AUTOSAR XML (schema 4-0-3)
standard types defined: Boolean, UInt8
package /AUTOSAR_Platform/DataConstrs
  range DC_Boolean: raw 0..1
package /DataTypes/Units
  unit NoUnit1: display-name=NoUnit, factor-si-to-unit=1, offset-si-to-unit=0
package /PATAC/Facility/DataTypes/Implementation
  compu method COMPU_Boolean: 0=FALSE, 1=TRUE
  unit NoUnit: factor-si-to-unit=1, offset-si-to-unit=0
package /PATAC/MSM/DataTypes/ImplementationDataTypes
  impl type IfVeSMSeStNumConfig: category=VALUE, base-type=UInt8, sw-calibration-access=READ-ONLY, compu {0=SeatNum4Config, 1=SeatNum6Config, 2=SeatNum7Config, 3=SeatNum4PConfig, 4=SeatNumNDLBLow, 5=SeatNumNDLBHigh}, type-emitter=RTE
  impl type IntCnt: category=VALUE, base-type=UInt8, sw-calibration-access=READ-ONLY, type-emitter=RTE
  impl type IntEnable: category=VALUE, base-type=Boolean, sw-calibration-access=READ-ONLY, type-emitter=RTE
package /PATAC/MSM/ModeAdjust
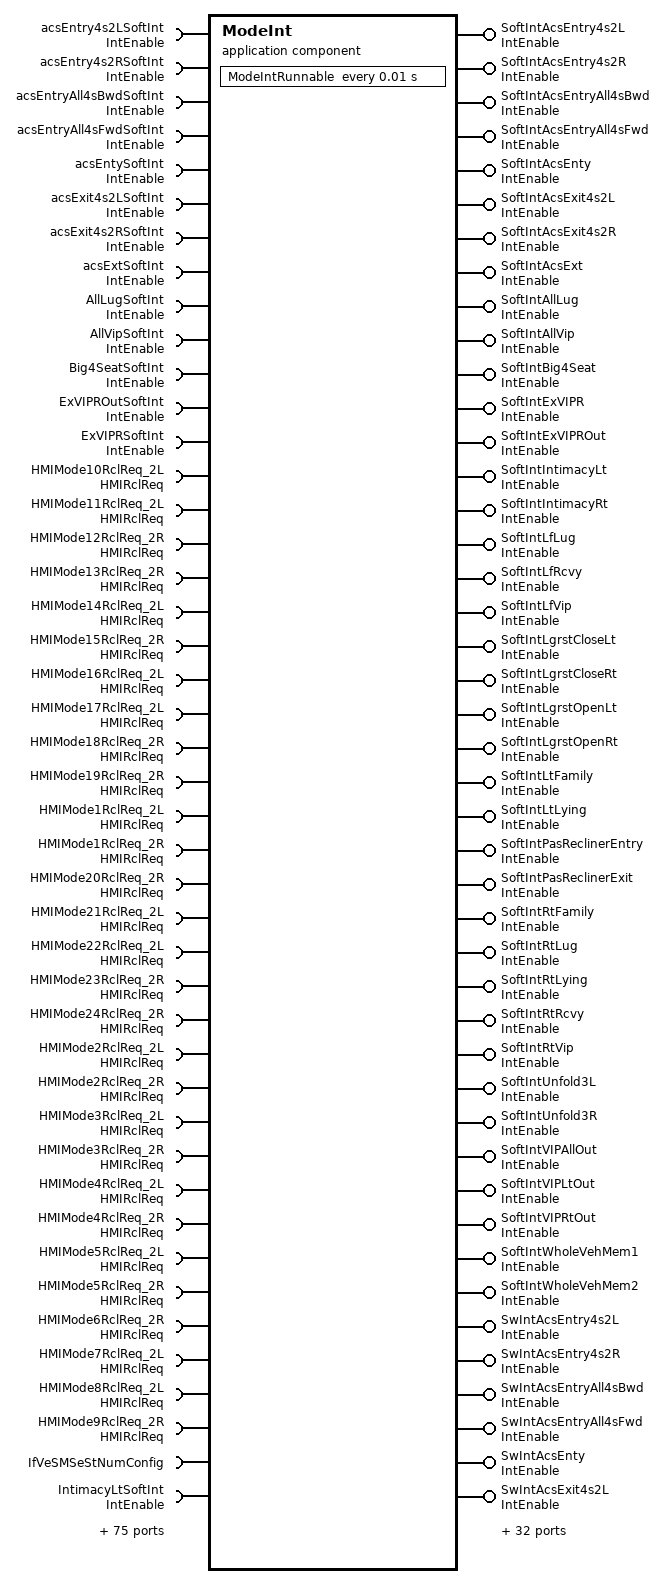
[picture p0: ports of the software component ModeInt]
  application sw component type ModeInt
    76 x provide port, all with provided-interface=IntEnable:
      SoftIntAcsEntry4s2L: nonqueued-sender-com-spec{data-element=IntEnable/Val, init-value=ComSpec59f96da2_7120eeaaf3e8fd53:0}
      SoftIntAcsEntry4s2R: nonqueued-sender-com-spec{data-element=IntEnable/Val, init-value=ComSpec188b96a0_423124f0f088183b:0}
      SoftIntAcsEntryAll4sBwd: nonqueued-sender-com-spec{data-element=IntEnable/Val, init-value=ComSpec659958fd_9c26f3706bd66cb5:0}
      SoftIntAcsEntryAll4sFwd: nonqueued-sender-com-spec{data-element=IntEnable/Val, init-value=ComSpec65858428_b3ed7bfb3665fd2b:0}
      SoftIntAcsEnty: nonqueued-sender-com-spec{data-element=IntEnable/Val, init-value=ComSpecc3d9fe5d_26040a192377f9e4:0}
      SoftIntAcsExit4s2L: nonqueued-sender-com-spec{data-element=IntEnable/Val, init-value=ComSpec2f50422d_f66996e724c9b7d0:0}
      SoftIntAcsExit4s2R: nonqueued-sender-com-spec{data-element=IntEnable/Val, init-value=ComSpeccde21871_e71db2d184100505:0}
      SoftIntAcsExt: nonqueued-sender-com-spec{data-element=IntEnable/Val, init-value=ComSpec899aba2d_12feed9e9f306d84:0}
      SoftIntAllLug: nonqueued-sender-com-spec{data-element=IntEnable/Val, init-value=ComSpecb3b8c25f_afafc56442f97f2f:0}
      SoftIntAllVip: nonqueued-sender-com-spec{data-element=IntEnable/Val, init-value=ComSpeca1d71ad4_c5481bbab1153ece:0}
      SoftIntBig4Seat: nonqueued-sender-com-spec{data-element=IntEnable/Val, init-value=0}
      SoftIntExVIPR: nonqueued-sender-com-spec{data-element=IntEnable/Val, init-value=0}
      SoftIntExVIPROut: nonqueued-sender-com-spec{data-element=IntEnable/Val, init-value=0}
      SoftIntIntimacyLt: nonqueued-sender-com-spec{data-element=IntEnable/Val, init-value=ComSpec179d4aec_8b8d804c9de5a832:0}
      SoftIntIntimacyRt: nonqueued-sender-com-spec{data-element=IntEnable/Val, init-value=ComSpece128a0c0_0fd8747b7173239b:0}
      SoftIntLfLug: nonqueued-sender-com-spec{data-element=IntEnable/Val, init-value=ComSpece807cf11_91c2ff9d50d5acbd:0}
      SoftIntLfRcvy: nonqueued-sender-com-spec{data-element=IntEnable/Val, init-value=ComSpecf2ff96a5_192105ae2675aaf7:0}
      SoftIntLfVip: nonqueued-sender-com-spec{data-element=IntEnable/Val, init-value=ComSpec8127e56c_ef9d14cff893367e:0}
      SoftIntLgrstCloseLt: nonqueued-sender-com-spec{data-element=IntEnable/Val, init-value=ComSpecd43ef14f_51d6d7e3885dd74d:0}
      SoftIntLgrstCloseRt: nonqueued-sender-com-spec{data-element=IntEnable/Val, init-value=ComSpecd6d83571_8de76a0bc78fde80:0}
      SoftIntLgrstOpenLt: nonqueued-sender-com-spec{data-element=IntEnable/Val, init-value=ComSpec41af1a4f_f741a1cbd52ea939:0}
      SoftIntLgrstOpenRt: nonqueued-sender-com-spec{data-element=IntEnable/Val, init-value=ComSpecbefe6405_6f1c2904a5660aca:0}
      SoftIntLtFamily: nonqueued-sender-com-spec{data-element=IntEnable/Val, init-value=ComSpecf3068dab_be17da265e3b369f:0}
      SoftIntLtLying: nonqueued-sender-com-spec{data-element=IntEnable/Val, init-value=ComSpec41634c5a_24a1ae597b892c7e:0}
      SoftIntPasReclinerEntry: nonqueued-sender-com-spec{data-element=IntEnable/Val, init-value=ComSpec5174c602_8624e7747eaef3d9:0}
      SoftIntPasReclinerExit: nonqueued-sender-com-spec{data-element=IntEnable/Val, init-value=ComSpec88456c9d_079221d12eb33f36:0}
      SoftIntRtFamily: nonqueued-sender-com-spec{data-element=IntEnable/Val, init-value=ComSpec6bdeb8e2_9f608aa14f83c2ef:0}
      SoftIntRtLug: nonqueued-sender-com-spec{data-element=IntEnable/Val, init-value=ComSpec31871b14_19a3da55a16d08b9:0}
      SoftIntRtLying: nonqueued-sender-com-spec{data-element=IntEnable/Val, init-value=ComSpecb43ed3d5_9c183203f17d7c39:0}
      SoftIntRtRcvy: nonqueued-sender-com-spec{data-element=IntEnable/Val, init-value=ComSpec0c8ac4fd_05f7ee5b718f0b60:0}
      SoftIntRtVip: nonqueued-sender-com-spec{data-element=IntEnable/Val, init-value=ComSpec0e3a052e_e0a08b00a2b52453:0}
      SoftIntUnfold3L: nonqueued-sender-com-spec{data-element=IntEnable/Val, init-value=0}
      SoftIntUnfold3R: nonqueued-sender-com-spec{data-element=IntEnable/Val, init-value=0}
      SoftIntVIPAllOut: nonqueued-sender-com-spec{data-element=IntEnable/Val, init-value=ComSpec9d458944_6a58e494fda9435a:0}
      SoftIntVIPLtOut: nonqueued-sender-com-spec{data-element=IntEnable/Val, init-value=ComSpec3fe9d267_b5ef9a6cf583b00d:0}
      SoftIntVIPRtOut: nonqueued-sender-com-spec{data-element=IntEnable/Val, init-value=ComSpec14da6a61_1cd6682ed1dd175b:0}
      SoftIntWholeVehMem1: nonqueued-sender-com-spec{data-element=IntEnable/Val, init-value=0}
      SoftIntWholeVehMem2: nonqueued-sender-com-spec{data-element=IntEnable/Val, init-value=0}
      SwIntAcsEntry4s2L: nonqueued-sender-com-spec{data-element=IntEnable/Val, init-value=ComSpec5b381a05_20a420dcaf653946:0}
      SwIntAcsEntry4s2R: nonqueued-sender-com-spec{data-element=IntEnable/Val, init-value=ComSpec08dbcf5e_623373ab2a54adc4:0}
      SwIntAcsEntryAll4sBwd: nonqueued-sender-com-spec{data-element=IntEnable/Val, init-value=ComSpec2acac57c_83e28e6252a86cec:0}
      SwIntAcsEntryAll4sFwd: nonqueued-sender-com-spec{data-element=IntEnable/Val, init-value=ComSpecb3bc0b71_9a1b690978a523bd:0}
      SwIntAcsEnty: nonqueued-sender-com-spec{data-element=IntEnable/Val, init-value=ComSpec815b8781_0bbd995141a2ae08:0}
      SwIntAcsExit4s2L: nonqueued-sender-com-spec{data-element=IntEnable/Val, init-value=ComSpecb208aba7_4f2c212f3d748e34:0}
      SwIntAcsExit4s2R: nonqueued-sender-com-spec{data-element=IntEnable/Val, init-value=ComSpecab9794b0_e6ed6e27ff51b9fa:0}
      SwIntAcsExt: nonqueued-sender-com-spec{data-element=IntEnable/Val, init-value=ComSpecd839f9e4_f74d7836726247ea:0}
      SwIntAllLug: nonqueued-sender-com-spec{data-element=IntEnable/Val, init-value=ComSpec1f44a83d_0c3f442d2dd8c614:0}
      SwIntAllVip: nonqueued-sender-com-spec{data-element=IntEnable/Val, init-value=ComSpeccc0c7db5_08b538b43a0752a9:0}
      SwIntAllVipOut: nonqueued-sender-com-spec{data-element=IntEnable/Val, init-value=0}
      SwIntBig4Seat: nonqueued-sender-com-spec{data-element=IntEnable/Val, init-value=0}
      SwIntExVIPR: nonqueued-sender-com-spec{data-element=IntEnable/Val, init-value=0}
      SwIntExVIPROut: nonqueued-sender-com-spec{data-element=IntEnable/Val, init-value=0}
      SwIntIntimacyLt: nonqueued-sender-com-spec{data-element=IntEnable/Val, init-value=ComSpeced1880dd_7f049cd17b79689a:0}
      SwIntIntimacyRt: nonqueued-sender-com-spec{data-element=IntEnable/Val, init-value=ComSpec82f33741_a070fa978900dd49:0}
      SwIntLfLug: nonqueued-sender-com-spec{data-element=IntEnable/Val, init-value=ComSpec1d835650_9f2d33f93bae7e2d:0}
      SwIntLfRcvy: nonqueued-sender-com-spec{data-element=IntEnable/Val, init-value=ComSpeca2d8a846_f1765e4b963d308a:0}
      SwIntLfVip: nonqueued-sender-com-spec{data-element=IntEnable/Val, init-value=ComSpec5ae82a95_8b538ef9cf021bb9:0}
      SwIntLfVipOut: nonqueued-sender-com-spec{data-element=IntEnable/Val, init-value=0}
      SwIntLgrstCloseLt: nonqueued-sender-com-spec{data-element=IntEnable/Val, init-value=ComSpec37957095_1f6be46bc34810ce:0}
      SwIntLgrstCloseRt: nonqueued-sender-com-spec{data-element=IntEnable/Val, init-value=ComSpec7bfebc29_3b30ba1fa7bdbeff:0}
      SwIntLgrstOpenLt: nonqueued-sender-com-spec{data-element=IntEnable/Val, init-value=ComSpecda775f0f_101109881c7da9c7:0}
      SwIntLgrstOpenRt: nonqueued-sender-com-spec{data-element=IntEnable/Val, init-value=ComSpec630e8cc5_d01f660af315f5d8:0}
      SwIntLtFamily: nonqueued-sender-com-spec{data-element=IntEnable/Val, init-value=ComSpeca8acf676_6206e2a0c6bca466:0}
      SwIntLtLying: nonqueued-sender-com-spec{data-element=IntEnable/Val, init-value=ComSpec22b14825_94d9dfc41c8f591b:0}
      SwIntPasReclinerEntry: nonqueued-sender-com-spec{data-element=IntEnable/Val, init-value=ComSpec2817485a_c93ad14cb402e925:0}
      SwIntPasReclinerExit: nonqueued-sender-com-spec{data-element=IntEnable/Val, init-value=ComSpecee27f8bf_7800ff2246ae725c:0}
      SwIntRtFamily: nonqueued-sender-com-spec{data-element=IntEnable/Val, init-value=ComSpecff73a571_d104911f83169a22:0}
      SwIntRtLug: nonqueued-sender-com-spec{data-element=IntEnable/Val, init-value=ComSpec73fd1a62_e7a0e89016c609a2:0}
      SwIntRtLying: nonqueued-sender-com-spec{data-element=IntEnable/Val, init-value=ComSpec24405ce7_da40e6512a24f22a:0}
      SwIntRtRcvy: nonqueued-sender-com-spec{data-element=IntEnable/Val, init-value=ComSpec96664597_38534832cbc35c95:0}
      SwIntRtVip: nonqueued-sender-com-spec{data-element=IntEnable/Val, init-value=ComSpec347f2341_073160147a5bf2ad:0}
      SwIntRtVipOut: nonqueued-sender-com-spec{data-element=IntEnable/Val, init-value=0}
      SwIntUnfold3L: nonqueued-sender-com-spec{data-element=IntEnable/Val, init-value=ComSpec5899eaf1_eb0de24a74093078:0}
      SwIntUnfold3R: nonqueued-sender-com-spec{data-element=IntEnable/Val, init-value=ComSpecc1b8f339_34e92b2b21141ee2:0}
      SwIntWholeVehMem1: nonqueued-sender-com-spec{data-element=IntEnable/Val, init-value=0}
      SwIntWholeVehMem2: nonqueued-sender-com-spec{data-element=IntEnable/Val, init-value=0}
    119 x require port:
      acsEntry4s2LSoftInt: nonqueued-receiver-com-spec{data-element=IntEnable/Val, filter=data-filter-type=ALWAYS, init-value=ComSpec59bedbba_d8fc4b3de43f23dd:0}, required-interface=IntEnable
      acsEntry4s2RSoftInt: nonqueued-receiver-com-spec{data-element=IntEnable/Val, filter=data-filter-type=ALWAYS, init-value=ComSpec9d818e9f_9fc340a7e822681f:0}, required-interface=IntEnable
      acsEntryAll4sBwdSoftInt: nonqueued-receiver-com-spec{data-element=IntEnable/Val, filter=data-filter-type=ALWAYS, init-value=ComSpecaae4a7d9_6114fb8456c149cb:0}, required-interface=IntEnable
      acsEntryAll4sFwdSoftInt: nonqueued-receiver-com-spec{data-element=IntEnable/Val, filter=data-filter-type=ALWAYS, init-value=ComSpec57ad5c21_c1c1b5a534bf99e5:0}, required-interface=IntEnable
      acsEntySoftInt: nonqueued-receiver-com-spec{data-element=IntEnable/Val, filter=data-filter-type=ALWAYS, init-value=0}, required-interface=IntEnable
      acsExit4s2LSoftInt: nonqueued-receiver-com-spec{data-element=IntEnable/Val, filter=data-filter-type=ALWAYS, init-value=ComSpec52c7b1c7_8f7410da7d11ef15:0}, required-interface=IntEnable
      acsExit4s2RSoftInt: nonqueued-receiver-com-spec{data-element=IntEnable/Val, filter=data-filter-type=ALWAYS, init-value=ComSpeccae1e112_0cd2aaa08630bc08:0}, required-interface=IntEnable
      acsExtSoftInt: nonqueued-receiver-com-spec{data-element=IntEnable/Val, filter=data-filter-type=ALWAYS, init-value=ComSpec1f971588_c2a00f428e3a637b:0}, required-interface=IntEnable
      AllLugSoftInt: nonqueued-receiver-com-spec{data-element=IntEnable/Val, filter=data-filter-type=ALWAYS, init-value=ComSpecdd839e1a_e693969bed64dde0:0}, required-interface=IntEnable
      AllVipSoftInt: nonqueued-receiver-com-spec{data-element=IntEnable/Val, filter=data-filter-type=ALWAYS, init-value=ComSpec3b97fd85_fa418b3abcd6b94f:0}, required-interface=IntEnable
      Big4SeatSoftInt: nonqueued-receiver-com-spec{data-element=IntEnable/Val, filter=data-filter-type=ALWAYS, init-value=0}, required-interface=IntEnable
      ExVIPROutSoftInt: nonqueued-receiver-com-spec{data-element=IntEnable/Val, filter=data-filter-type=ALWAYS, init-value=0}, required-interface=IntEnable
      ExVIPRSoftInt: nonqueued-receiver-com-spec{data-element=IntEnable/Val, filter=data-filter-type=ALWAYS, init-value=0}, required-interface=IntEnable
      HMIMode10RclReq_2L: nonqueued-receiver-com-spec{data-element=HMIRclReq/Val, filter=data-filter-type=ALWAYS, init-value=ComSpec48ec700f_8358f5fc2fa971fa:0}, required-interface=HMIRclReq
      HMIMode11RclReq_2L: nonqueued-receiver-com-spec{data-element=HMIRclReq/Val, filter=data-filter-type=ALWAYS, init-value=ComSpecf1b919ee_24d06a054ca132ae:0}, required-interface=HMIRclReq
      HMIMode12RclReq_2R: nonqueued-receiver-com-spec{data-element=HMIRclReq/Val, filter=data-filter-type=ALWAYS, init-value=ComSpec2f37a205_f0a2b0e5e5a48147:0}, required-interface=HMIRclReq
      HMIMode13RclReq_2R: nonqueued-receiver-com-spec{data-element=HMIRclReq/Val, filter=data-filter-type=ALWAYS, init-value=ComSpecd52c478e_80f8ef58ce4007b5:0}, required-interface=HMIRclReq
      HMIMode14RclReq_2L: nonqueued-receiver-com-spec{data-element=HMIRclReq/Val, filter=data-filter-type=ALWAYS, init-value=ComSpecbcd2590a_48ea2252ac4ce66f:0}, required-interface=HMIRclReq
      HMIMode15RclReq_2R: nonqueued-receiver-com-spec{data-element=HMIRclReq/Val, filter=data-filter-type=ALWAYS, init-value=ComSpecb4ac5533_ffddfb15281a2e63:0}, required-interface=HMIRclReq
      HMIMode16RclReq_2L: nonqueued-receiver-com-spec{data-element=HMIRclReq/Val, filter=data-filter-type=ALWAYS, init-value=ComSpecf0596a86_9f1e0c3bcce4b0de:0}, required-interface=HMIRclReq
      HMIMode17RclReq_2L: nonqueued-receiver-com-spec{data-element=HMIRclReq/Val, filter=data-filter-type=ALWAYS, init-value=ComSpec8054f467_c7203278fbf5529d:0}, required-interface=HMIRclReq
      HMIMode18RclReq_2R: nonqueued-receiver-com-spec{data-element=HMIRclReq/Val, filter=data-filter-type=ALWAYS, init-value=ComSpecd909c3ef_61204d4323339b3e:0}, required-interface=HMIRclReq
      HMIMode19RclReq_2R: nonqueued-receiver-com-spec{data-element=HMIRclReq/Val, filter=data-filter-type=ALWAYS, init-value=ComSpeca16d1fe6_37f1405389d467af:0}, required-interface=HMIRclReq
      HMIMode1RclReq_2L: nonqueued-receiver-com-spec{data-element=HMIRclReq/Val, filter=data-filter-type=ALWAYS, init-value=ComSpec87a649c6_5ba2898635411627:0}, required-interface=HMIRclReq
      HMIMode1RclReq_2R: nonqueued-receiver-com-spec{data-element=HMIRclReq/Val, filter=data-filter-type=ALWAYS, init-value=ComSpec08373bea_a271b1267ea2ca8b:0}, required-interface=HMIRclReq
      HMIMode20RclReq_2R: nonqueued-receiver-com-spec{data-element=HMIRclReq/Val, filter=data-filter-type=ALWAYS, init-value=ComSpecd2ca0f4f_9a6b416a4d7d2267:0}, required-interface=HMIRclReq
      HMIMode21RclReq_2L: nonqueued-receiver-com-spec{data-element=HMIRclReq/Val, filter=data-filter-type=ALWAYS, init-value=ComSpec9bb24149_b12d629b0469cc41:0}, required-interface=HMIRclReq
      HMIMode22RclReq_2L: nonqueued-receiver-com-spec{data-element=HMIRclReq/Val, filter=data-filter-type=ALWAYS, init-value=ComSpec399996ab_be8717f416b5fb71:0}, required-interface=HMIRclReq
      HMIMode23RclReq_2R: nonqueued-receiver-com-spec{data-element=HMIRclReq/Val, filter=data-filter-type=ALWAYS, init-value=ComSpec0396326d_ae5d643e63f9509f:0}, required-interface=HMIRclReq
      HMIMode24RclReq_2R: nonqueued-receiver-com-spec{data-element=HMIRclReq/Val, filter=data-filter-type=ALWAYS, init-value=ComSpec24f8b7e1_6fbf0aebf138903a:0}, required-interface=HMIRclReq
      HMIMode2RclReq_2L: nonqueued-receiver-com-spec{data-element=HMIRclReq/Val, filter=data-filter-type=ALWAYS, init-value=ComSpec6244e29c_b02d9b574a1fabcd:0}, required-interface=HMIRclReq
      HMIMode2RclReq_2R: nonqueued-receiver-com-spec{data-element=HMIRclReq/Val, filter=data-filter-type=ALWAYS, init-value=ComSpecb3d4c087_476a81386f50bd44:0}, required-interface=HMIRclReq
      HMIMode3RclReq_2L: nonqueued-receiver-com-spec{data-element=HMIRclReq/Val, filter=data-filter-type=ALWAYS, init-value=ComSpecd07aee59_339ce832ecf1f1a3:0}, required-interface=HMIRclReq
      HMIMode3RclReq_2R: nonqueued-receiver-com-spec{data-element=HMIRclReq/Val, filter=data-filter-type=ALWAYS, init-value=ComSpec5395d52f_89d78e9fa428599d:0}, required-interface=HMIRclReq
      HMIMode4RclReq_2L: nonqueued-receiver-com-spec{data-element=HMIRclReq/Val, filter=data-filter-type=ALWAYS, init-value=ComSpecafd3ef83_549d381d90760e9a:0}, required-interface=HMIRclReq
      HMIMode4RclReq_2R: nonqueued-receiver-com-spec{data-element=HMIRclReq/Val, filter=data-filter-type=ALWAYS, init-value=ComSpec38355e99_bd382d68658e5a19:0}, required-interface=HMIRclReq
      HMIMode5RclReq_2L: nonqueued-receiver-com-spec{data-element=HMIRclReq/Val, filter=data-filter-type=ALWAYS, init-value=ComSpecf3ab2b03_be24caa6a8129f90:0}, required-interface=HMIRclReq
      HMIMode5RclReq_2R: nonqueued-receiver-com-spec{data-element=HMIRclReq/Val, filter=data-filter-type=ALWAYS, init-value=ComSpec80c794a8_d3f2d54c61da4b4a:0}, required-interface=HMIRclReq
      HMIMode6RclReq_2R: nonqueued-receiver-com-spec{data-element=HMIRclReq/Val, filter=data-filter-type=ALWAYS, init-value=ComSpec8ed9bac5_62447ecaf3e156e1:0}, required-interface=HMIRclReq
      HMIMode7RclReq_2L: nonqueued-receiver-com-spec{data-element=HMIRclReq/Val, filter=data-filter-type=ALWAYS, init-value=ComSpec4eaa22df_06f5da83a7095015:0}, required-interface=HMIRclReq
      HMIMode8RclReq_2L: nonqueued-receiver-com-spec{data-element=HMIRclReq/Val, filter=data-filter-type=ALWAYS, init-value=ComSpece2940852_d5b05565cb3e6174:0}, required-interface=HMIRclReq
      HMIMode9RclReq_2R: nonqueued-receiver-com-spec{data-element=HMIRclReq/Val, filter=data-filter-type=ALWAYS, init-value=ComSpece38ed45c_1b264e5b2bfc9c6f:0}, required-interface=HMIRclReq
      IfVeSMSeStNumConfig: nonqueued-receiver-com-spec{data-element=IfVeSMSeStNumConfig/Val, filter=data-filter-type=ALWAYS, init-value=ComSpecf727fae3_2143c49204634035:2}, required-interface=IfVeSMSeStNumConfig
      IntimacyLtSoftInt: nonqueued-receiver-com-spec{data-element=IntEnable/Val, filter=data-filter-type=ALWAYS, init-value=ComSpecc094951b_d82b9a4163a0e180:0}, required-interface=IntEnable
      IntimacyRtSoftInt: nonqueued-receiver-com-spec{data-element=IntEnable/Val, filter=data-filter-type=ALWAYS, init-value=ComSpec846f0d91_0e7f980c87f69956:0}, required-interface=IntEnable
      Is2LStSwAct: nonqueued-receiver-com-spec{data-element=SeatSwActive/Val, filter=data-filter-type=ALWAYS, init-value=0}, required-interface=SeatSwActive
      Is2RStSwAct: nonqueued-receiver-com-spec{data-element=SeatSwActive/Val, filter=data-filter-type=ALWAYS, init-value=ComSpecca1ec7b7_4456209d609d9311:0}, required-interface=SeatSwActive
      Is3LStSwAct: nonqueued-receiver-com-spec{data-element=SeatSwActive/Val, filter=data-filter-type=ALWAYS, init-value=ComSpec4213ca9a_e561e20e65899db3:0}, required-interface=SeatSwActive
      Is3RStSwAct: nonqueued-receiver-com-spec{data-element=SeatSwActive/Val, filter=data-filter-type=ALWAYS, init-value=ComSpec9e9e183a_d622ea5f5fc4dba6:0}, required-interface=SeatSwActive
      IsDrvStSwAct: nonqueued-receiver-com-spec{data-element=SeatSwActive/Val, filter=data-filter-type=ALWAYS, init-value=ComSpec2a1568ad_64fd73844f4ad507:0}, required-interface=SeatSwActive
      IsPasStSwAct: nonqueued-receiver-com-spec{data-element=SeatSwActive/Val, filter=data-filter-type=ALWAYS, init-value=ComSpec60856aab_c7fe75bd68ca827f:0}, required-interface=SeatSwActive
      LgrstCloseLtSoftInt: nonqueued-receiver-com-spec{data-element=IntEnable/Val, filter=data-filter-type=ALWAYS, init-value=ComSpec5028d4e5_e2f8f108efe8dd3a:0}, required-interface=IntEnable
      LgrstCloseRtSoftInt: nonqueued-receiver-com-spec{data-element=IntEnable/Val, filter=data-filter-type=ALWAYS, init-value=ComSpecce9a2399_a46f9232b75b9152:0}, required-interface=IntEnable
      LgrstOpenLtSoftInt: nonqueued-receiver-com-spec{data-element=IntEnable/Val, filter=data-filter-type=ALWAYS, init-value=ComSpec4f247cc6_b0f527fd143c35f2:0}, required-interface=IntEnable
      LgrstOpenRtSoftInt: nonqueued-receiver-com-spec{data-element=IntEnable/Val, filter=data-filter-type=ALWAYS, init-value=ComSpec0fc785ff_438adf1e5a24948d:0}, required-interface=IntEnable
      LtFamilySoftInt: nonqueued-receiver-com-spec{data-element=IntEnable/Val, filter=data-filter-type=ALWAYS, init-value=ComSpec271dc458_d5fac3b6bb4d312b:0}, required-interface=IntEnable
      LtLugSoftInt: nonqueued-receiver-com-spec{data-element=IntEnable/Val, filter=data-filter-type=ALWAYS, init-value=ComSpec0c2b0d4a_d62b1a7385d46b13:0}, required-interface=IntEnable
      LtLyingSoftInt: nonqueued-receiver-com-spec{data-element=IntEnable/Val, filter=data-filter-type=ALWAYS, init-value=ComSpec054a1bf0_efd9aa4cb20591f9:0}, required-interface=IntEnable
      LtRcvySoftInt: nonqueued-receiver-com-spec{data-element=IntEnable/Val, filter=data-filter-type=ALWAYS, init-value=ComSpec5795f686_21953a855b298cd8:0}, required-interface=IntEnable
      LtVipSoftInt: nonqueued-receiver-com-spec{data-element=IntEnable/Val, filter=data-filter-type=ALWAYS, init-value=ComSpec62c455bb_63fe6cdef1daa09c:0}, required-interface=IntEnable
      PasReclinerEntrySoftInt: nonqueued-receiver-com-spec{data-element=IntEnable/Val, filter=data-filter-type=ALWAYS, init-value=ComSpec2a424904_8a7c4d979181123b:0}, required-interface=IntEnable
      PasReclinerExitSoftInt: nonqueued-receiver-com-spec{data-element=IntEnable/Val, filter=data-filter-type=ALWAYS, init-value=ComSpec5b39955b_7d8525146086194f:0}, required-interface=IntEnable
      RtFamilySoftInt: nonqueued-receiver-com-spec{data-element=IntEnable/Val, filter=data-filter-type=ALWAYS, init-value=ComSpeca76c63bf_bca7a4dd64ddd3ca:0}, required-interface=IntEnable
      RtLugSoftInt: nonqueued-receiver-com-spec{data-element=IntEnable/Val, filter=data-filter-type=ALWAYS, init-value=ComSpec48107096_5d3feae5e45eb01c:0}, required-interface=IntEnable
      RtLyingSoftInt: nonqueued-receiver-com-spec{data-element=IntEnable/Val, filter=data-filter-type=ALWAYS, init-value=ComSpecfbf2f4d8_0e877721369faf7e:0}, required-interface=IntEnable
      RtRcvySoftInt: nonqueued-receiver-com-spec{data-element=IntEnable/Val, filter=data-filter-type=ALWAYS, init-value=ComSpec61c7ac5d_27582d4b642bb77e:0}, required-interface=IntEnable
      RtVipSoftInt: nonqueued-receiver-com-spec{data-element=IntEnable/Val, filter=data-filter-type=ALWAYS, init-value=ComSpec78ed9d43_2188a50c674b1529:0}, required-interface=IntEnable
      SRSAcsEntry4s2LIntCnt: nonqueued-receiver-com-spec{data-element=SwModeIntCnt/Val, filter=data-filter-type=ALWAYS, init-value=ComSpeca6d38231_29060a7aec622ad4:0}, required-interface=SwModeIntCnt
      SRSAcsEntry4s2RIntCnt: nonqueued-receiver-com-spec{data-element=SwModeIntCnt/Val, filter=data-filter-type=ALWAYS, init-value=ComSpec3f1d777a_a93096877cacc308:0}, required-interface=SwModeIntCnt
      SRSAcsEntyIntCnt: nonqueued-receiver-com-spec{data-element=SwModeIntCnt/Val, filter=data-filter-type=ALWAYS, init-value=ComSpecf3835234_973640c0ae377916:0}, required-interface=SwModeIntCnt
      SRSAcsExit4s2LIntCnt: nonqueued-receiver-com-spec{data-element=SwModeIntCnt/Val, filter=data-filter-type=ALWAYS, init-value=ComSpec648523ed_137c4fe872a5252e:0}, required-interface=SwModeIntCnt
      SRSAcsExit4s2RIntCnt: nonqueued-receiver-com-spec{data-element=SwModeIntCnt/Val, filter=data-filter-type=ALWAYS, init-value=ComSpecee631c97_279a66fcc4f750fe:0}, required-interface=SwModeIntCnt
      SRSAcsExtIntCnt: nonqueued-receiver-com-spec{data-element=SwModeIntCnt/Val, filter=data-filter-type=ALWAYS, init-value=ComSpec19100bc3_981d13dc6033ee0f:0}, required-interface=SwModeIntCnt
      SRSAllLugIntCnt: nonqueued-receiver-com-spec{data-element=SwModeIntCnt/Val, filter=data-filter-type=ALWAYS, init-value=ComSpec7f63ef5e_dea1ebb6fb79323a:0}, required-interface=SwModeIntCnt
      SRSAllVipIntCnt: nonqueued-receiver-com-spec{data-element=SwModeIntCnt/Val, filter=data-filter-type=ALWAYS, init-value=ComSpec498ba091_d4ba8e556244eca7:0}, required-interface=SwModeIntCnt
      SRSIntimacyLtIntCnt: nonqueued-receiver-com-spec{data-element=SwModeIntCnt/Val, filter=data-filter-type=ALWAYS, init-value=ComSpec5c491241_6779e337b4d4da86:0}, required-interface=SwModeIntCnt
      SRSIntimacyRtIntCnt: nonqueued-receiver-com-spec{data-element=SwModeIntCnt/Val, filter=data-filter-type=ALWAYS, init-value=ComSpecf76ae19b_4e36707b57db5317:0}, required-interface=SwModeIntCnt
      SRSLgrstCloseLtIntCnt: nonqueued-receiver-com-spec{data-element=SwModeIntCnt/Val, filter=data-filter-type=ALWAYS, init-value=ComSpecd1c7a8aa_7cb2f1dcbc4d29de:0}, required-interface=SwModeIntCnt
      SRSLgrstCloseRtIntCnt: nonqueued-receiver-com-spec{data-element=SwModeIntCnt/Val, filter=data-filter-type=ALWAYS, init-value=ComSpec4a354879_c28bfd0dbb9ef2b5:0}, required-interface=SwModeIntCnt
      SRSLgrstOpenLtIntCnt: nonqueued-receiver-com-spec{data-element=SwModeIntCnt/Val, filter=data-filter-type=ALWAYS, init-value=ComSpec8e4ebe82_9c22ce939bba79fa:0}, required-interface=SwModeIntCnt
      SRSLgrstOpenRtIntCnt: nonqueued-receiver-com-spec{data-element=SwModeIntCnt/Val, filter=data-filter-type=ALWAYS, init-value=ComSpecd1d36161_01f4a503ae1fc52f:0}, required-interface=SwModeIntCnt
      SRSLtFamilyIntCnt: nonqueued-receiver-com-spec{data-element=SwModeIntCnt/Val, filter=data-filter-type=ALWAYS, init-value=ComSpec992a5651_8f31ef3cbebf4e29:0}, required-interface=SwModeIntCnt
      SRSLtLugIntCnt: nonqueued-receiver-com-spec{data-element=SwModeIntCnt/Val, filter=data-filter-type=ALWAYS, init-value=ComSpec2868b2c5_6137b34cd3dec42a:0}, required-interface=SwModeIntCnt
      SRSLtLyingIntCnt: nonqueued-receiver-com-spec{data-element=SwModeIntCnt/Val, filter=data-filter-type=ALWAYS, init-value=ComSpec097f2238_08870c6a1a5136c1:0}, required-interface=SwModeIntCnt
      SRSLtRcvyIntCnt: nonqueued-receiver-com-spec{data-element=SwModeIntCnt/Val, filter=data-filter-type=ALWAYS, init-value=ComSpecf498e187_12ad84783dc62990:0}, required-interface=SwModeIntCnt
      SRSLtVipIntCnt: nonqueued-receiver-com-spec{data-element=SwModeIntCnt/Val, filter=data-filter-type=ALWAYS, init-value=ComSpec59d42c89_1aef2beed199f7f1:0}, required-interface=SwModeIntCnt
      SRSRtFamilyIntCnt: nonqueued-receiver-com-spec{data-element=SwModeIntCnt/Val, filter=data-filter-type=ALWAYS, init-value=ComSpec29a1ebe2_9c46f5f4a36758e8:0}, required-interface=SwModeIntCnt
      SRSRtLugIntCnt: nonqueued-receiver-com-spec{data-element=SwModeIntCnt/Val, filter=data-filter-type=ALWAYS, init-value=ComSpec009663b4_2c25255925aeb196:0}, required-interface=SwModeIntCnt
      SRSRtLyingIntCnt: nonqueued-receiver-com-spec{data-element=SwModeIntCnt/Val, filter=data-filter-type=ALWAYS, init-value=ComSpec29627e4d_841a3d03e14f2d38:0}, required-interface=SwModeIntCnt
      SRSRtRcvyIntCnt: nonqueued-receiver-com-spec{data-element=SwModeIntCnt/Val, filter=data-filter-type=ALWAYS, init-value=ComSpec376e6940_5b14e1041789e295:0}, required-interface=SwModeIntCnt
      SRSRtVipIntCnt: nonqueued-receiver-com-spec{data-element=SwModeIntCnt/Val, filter=data-filter-type=ALWAYS, init-value=ComSpec1fdf6a03_cc95a7ba056b96ba:0}, required-interface=SwModeIntCnt
      StPassCmprtMdHMIReq: nonqueued-receiver-com-spec{data-element=StPassCmprtMdHMIReq/Val, filter=data-filter-type=ALWAYS, init-value=ComSpecb3c6e8e1_8597b9978d4f0ec1:0}, required-interface=StPassCmprtMdHMIReq
      SwAcsEntry4s2LIntCnt: nonqueued-receiver-com-spec{data-element=SwModeIntCnt/Val, filter=data-filter-type=ALWAYS, init-value=ComSpec0cce7286_1d3db4c6df3ee6ad:0}, required-interface=SwModeIntCnt
      SwAcsEntry4s2RIntCnt: nonqueued-receiver-com-spec{data-element=SwModeIntCnt/Val, filter=data-filter-type=ALWAYS, init-value=ComSpecd416470b_46f3c613cd10372c:0}, required-interface=SwModeIntCnt
      SwAcsEntyBIntCnt: nonqueued-receiver-com-spec{data-element=SwModeIntCnt/Val, filter=data-filter-type=ALWAYS, init-value=ComSpec9bc790c3_b040e0f8b8c979dd:0}, required-interface=SwModeIntCnt
      SwAcsEntyLIntCnt: nonqueued-receiver-com-spec{data-element=SwModeIntCnt/Val, filter=data-filter-type=ALWAYS, init-value=ComSpec58a5e124_862a27e3b5600d0a:0}, required-interface=SwModeIntCnt
      SwAcsEntyRIntCnt: nonqueued-receiver-com-spec{data-element=SwModeIntCnt/Val, filter=data-filter-type=ALWAYS, init-value=ComSpec7de52f16_c8d1e2af312be2f9:0}, required-interface=SwModeIntCnt
      SwAcsExit4s2LIntCnt: nonqueued-receiver-com-spec{data-element=SwModeIntCnt/Val, filter=data-filter-type=ALWAYS, init-value=ComSpec23ef021b_ccfba709831a744c:0}, required-interface=SwModeIntCnt
      SwAcsExit4s2RIntCnt: nonqueued-receiver-com-spec{data-element=SwModeIntCnt/Val, filter=data-filter-type=ALWAYS, init-value=ComSpec079ca5ba_c4f6564dcf59712f:0}, required-interface=SwModeIntCnt
      SwAcsExtLIntCnt: nonqueued-receiver-com-spec{data-element=SwModeIntCnt/Val, filter=data-filter-type=ALWAYS, init-value=ComSpeccb9381fd_381d5fa383734d3b:0}, required-interface=SwModeIntCnt
      SwAcsExtRIntCnt: nonqueued-receiver-com-spec{data-element=SwModeIntCnt/Val, filter=data-filter-type=ALWAYS, init-value=ComSpec02651811_52c0b5c18a7a94fc:0}, required-interface=SwModeIntCnt
      SwAllLugIntCnt: nonqueued-receiver-com-spec{data-element=SwModeIntCnt/Val, filter=data-filter-type=ALWAYS, init-value=ComSpecce01d1d5_a5f851cff8884ed4:0}, required-interface=SwModeIntCnt
      SwLfVipIntCnt: nonqueued-receiver-com-spec{data-element=SwModeIntCnt/Val, filter=data-filter-type=ALWAYS, init-value=ComSpecd605920e_159265bb4097a4be:0}, required-interface=SwModeIntCnt
      SwLtLugIntCnt: nonqueued-receiver-com-spec{data-element=SwModeIntCnt/Val, filter=data-filter-type=ALWAYS, init-value=ComSpec6592061b_c7f2c7f97e62bcf1:0}, required-interface=SwModeIntCnt
      SwLtRcvyIntCnt: nonqueued-receiver-com-spec{data-element=SwModeIntCnt/Val, filter=data-filter-type=ALWAYS, init-value=ComSpec97b5a781_5fae8b1f0f426d45:0}, required-interface=SwModeIntCnt
      SwPasReclinerEntryIntCnt: nonqueued-receiver-com-spec{data-element=SwModeIntCnt/Val, filter=data-filter-type=ALWAYS, init-value=ComSpecea8d83fb_b14d14aeaab0750d:0}, required-interface=SwModeIntCnt
      SwPasReclinerExitIntCnt: nonqueued-receiver-com-spec{data-element=SwModeIntCnt/Val, filter=data-filter-type=ALWAYS, init-value=ComSpec848a519f_df3f399df588dda4:0}, required-interface=SwModeIntCnt
      SwRtLugIntCnt: nonqueued-receiver-com-spec{data-element=SwModeIntCnt/Val, filter=data-filter-type=ALWAYS, init-value=ComSpec58263346_278dd0dd19881f80:0}, required-interface=SwModeIntCnt
      SwRtRcvyIntCnt: nonqueued-receiver-com-spec{data-element=SwModeIntCnt/Val, filter=data-filter-type=ALWAYS, init-value=ComSpec6f9d638b_19f64977e2ae2203:0}, required-interface=SwModeIntCnt
      SwRtVipIntCnt: nonqueued-receiver-com-spec{data-element=SwModeIntCnt/Val, filter=data-filter-type=ALWAYS, init-value=ComSpecfaf383cc_bafa77758acec661:0}, required-interface=SwModeIntCnt
      SwUnfold3LIntCnt: nonqueued-receiver-com-spec{data-element=SwModeIntCnt/Val, filter=data-filter-type=ALWAYS, init-value=ComSpec8ef848fc_9d831e9fc5af44d4:0}, required-interface=SwModeIntCnt
      SwUnfold3RIntCnt: nonqueued-receiver-com-spec{data-element=SwModeIntCnt/Val, filter=data-filter-type=ALWAYS, init-value=ComSpecaa2d1207_0b543380d413cbfa:0}, required-interface=SwModeIntCnt
      Unfold3LSoftInt: nonqueued-receiver-com-spec{data-element=IntEnable/Val, filter=data-filter-type=ALWAYS, init-value=0}, required-interface=IntEnable
      Unfold3RSoftInt: nonqueued-receiver-com-spec{data-element=IntEnable/Val, filter=data-filter-type=ALWAYS, init-value=0}, required-interface=IntEnable
      VIPAllOutSoftInt: nonqueued-receiver-com-spec{data-element=IntEnable/Val, filter=data-filter-type=ALWAYS, init-value=ComSpecd22ea045_35e05d9ba2724903:0}, required-interface=IntEnable
      VIPLtOutSoftInt: nonqueued-receiver-com-spec{data-element=IntEnable/Val, filter=data-filter-type=ALWAYS, init-value=ComSpec54a390d1_fa008e474ddcf622:0}, required-interface=IntEnable
      VIPRtOutSoftInt: nonqueued-receiver-com-spec{data-element=IntEnable/Val, filter=data-filter-type=ALWAYS, init-value=ComSpec85603f38_3e579aa35b0171c5:0}, required-interface=IntEnable
      WholeVehMem1SoftInt: nonqueued-receiver-com-spec{data-element=IntEnable/Val, filter=data-filter-type=ALWAYS, init-value=0}, required-interface=IntEnable
      WholeVehMem2SoftInt: nonqueued-receiver-com-spec{data-element=IntEnable/Val, filter=data-filter-type=ALWAYS, init-value=0}, required-interface=IntEnable
    behavior ModeInt_InternalBehavior
      timing event TMT_ModeIntRunnable: start-on-event=ModeIntRunnable, period=0.01
      runnable ModeIntRunnable: minimum-start-interval=0.01
        data-receive-point-by-arguments:
          119 x access:
            REC_acsEntry4s2LSoftInt_Val: accessed-variable=acsEntry4s2LSoftInt.Val
            REC_acsEntry4s2RSoftInt_Val: accessed-variable=acsEntry4s2RSoftInt.Val
            REC_acsEntryAll4sBwdSoftInt_Val: accessed-variable=acsEntryAll4sBwdSoftInt.Val
            REC_acsEntryAll4sFwdSoftInt_Val: accessed-variable=acsEntryAll4sFwdSoftInt.Val
            REC_acsEntySoftInt_Val: accessed-variable=acsEntySoftInt.Val
            REC_acsExit4s2LSoftInt_Val: accessed-variable=acsExit4s2LSoftInt.Val
            REC_acsExit4s2RSoftInt_Val: accessed-variable=acsExit4s2RSoftInt.Val
            REC_acsExtSoftInt_Val: accessed-variable=acsExtSoftInt.Val
            REC_AllLugSoftInt_Val: accessed-variable=AllLugSoftInt.Val
            REC_AllVipSoftInt_Val: accessed-variable=AllVipSoftInt.Val
            REC_Big4SeatSoftInt_Val: accessed-variable=Big4SeatSoftInt.Val
            REC_ExVIPROutSoftInt_Val: accessed-variable=ExVIPROutSoftInt.Val
            REC_ExVIPRSoftInt_Val: accessed-variable=ExVIPRSoftInt.Val
            REC_FamilyLtSoftInt_Val: accessed-variable=LtFamilySoftInt.Val
            REC_FamilyRtSoftInt_Val: accessed-variable=RtFamilySoftInt.Val
            REC_HMIMode10RclReq_Val: accessed-variable=HMIMode10RclReq_2L.Val
            REC_HMIMode11RclReq_Val: accessed-variable=HMIMode11RclReq_2L.Val
            REC_HMIMode12RclReq_2R_Val: accessed-variable=HMIMode12RclReq_2R.Val
            REC_HMIMode13RclReq_2R_Val: accessed-variable=HMIMode13RclReq_2R.Val
            REC_HMIMode14RclReq_2L_Val: accessed-variable=HMIMode14RclReq_2L.Val
            REC_HMIMode15RclReq_2R_Val: accessed-variable=HMIMode15RclReq_2R.Val
            REC_HMIMode16RclReq_2L_Val: accessed-variable=HMIMode16RclReq_2L.Val
            REC_HMIMode17RclReq_2L_Val: accessed-variable=HMIMode17RclReq_2L.Val
            REC_HMIMode18RclReq_2R_Val: accessed-variable=HMIMode18RclReq_2R.Val
            REC_HMIMode19RclReq_2R_Val: accessed-variable=HMIMode19RclReq_2R.Val
            REC_HMIMode1RclReq_2L_Val: accessed-variable=HMIMode1RclReq_2L.Val
            REC_HMIMode1RclReq_2R_Val: accessed-variable=HMIMode1RclReq_2R.Val
            REC_HMIMode20RclReq_2R_Val: accessed-variable=HMIMode20RclReq_2R.Val
            REC_HMIMode21RclReq_2L_Val: accessed-variable=HMIMode21RclReq_2L.Val
            REC_HMIMode22RclReq_2L_Val: accessed-variable=HMIMode22RclReq_2L.Val
            REC_HMIMode23RclReq_2R_Val: accessed-variable=HMIMode23RclReq_2R.Val
            REC_HMIMode24RclReq_2R_Val: accessed-variable=HMIMode24RclReq_2R.Val
            REC_HMIMode2RclReq_2L_Val: accessed-variable=HMIMode2RclReq_2L.Val
            REC_HMIMode2RclReq_2R_Val: accessed-variable=HMIMode2RclReq_2R.Val
            REC_HMIMode3RclReq_2L_Val: accessed-variable=HMIMode3RclReq_2L.Val
            REC_HMIMode3RclReq_2R_Val: accessed-variable=HMIMode3RclReq_2R.Val
            REC_HMIMode4RclReq_2R_Val: accessed-variable=HMIMode4RclReq_2R.Val
            REC_HMIMode4RclReq_Val: accessed-variable=HMIMode4RclReq_2L.Val
            REC_HMIMode5RclReq_2L_Val: accessed-variable=HMIMode5RclReq_2L.Val
            REC_HMIMode5RclReq_2R_Val: accessed-variable=HMIMode5RclReq_2R.Val
            REC_HMIMode6RclReq_2R_Val: accessed-variable=HMIMode6RclReq_2R.Val
            REC_HMIMode7RclReq_2L_Val: accessed-variable=HMIMode7RclReq_2L.Val
            REC_HMIMode8RclReq_2L_Val: accessed-variable=HMIMode8RclReq_2L.Val
            REC_HMIMode9RclReq_2R_Val: accessed-variable=HMIMode9RclReq_2R.Val
            REC_IfVeSMSeStNumConfig_Val: accessed-variable=IfVeSMSeStNumConfig.Val
            REC_IntimacyRtSoftInt_Val: accessed-variable=IntimacyRtSoftInt.Val
            REC_IntimacySoftInt_Val: accessed-variable=IntimacyLtSoftInt.Val
            REC_Is2LStSwAct_Val: accessed-variable=Is2LStSwAct.Val
            REC_Is2RStSwAct_Val: accessed-variable=Is2RStSwAct.Val
            REC_Is3LStSwAct_Val: accessed-variable=Is3LStSwAct.Val
            REC_Is3RStSwAct_Val: accessed-variable=Is3RStSwAct.Val
            REC_IsDrvStSwAct_Val: accessed-variable=IsDrvStSwAct.Val
            REC_IsPasStSwAct_Val: accessed-variable=IsPasStSwAct.Val
            REC_LgrstCloseLtSoftInt_Val: accessed-variable=LgrstCloseLtSoftInt.Val
            REC_LgrstCloseRtSoftInt_Val: accessed-variable=LgrstCloseRtSoftInt.Val
            REC_LgrstOpenLtSoftInt_Val: accessed-variable=LgrstOpenLtSoftInt.Val
            REC_LgrstOpenRtSoftInt_Val: accessed-variable=LgrstOpenRtSoftInt.Val
            REC_LtLugSoftInt_Val: accessed-variable=LtLugSoftInt.Val
            REC_LtRcvySoftInt_Val: accessed-variable=LtRcvySoftInt.Val
            REC_LtVipSoftInt_Val: accessed-variable=LtVipSoftInt.Val
            REC_LyingLtSoftInt_Val: accessed-variable=LtLyingSoftInt.Val
            REC_LyingRtSoftInt_Val: accessed-variable=RtLyingSoftInt.Val
            REC_PasReclinerEntrySoftInt_Val: accessed-variable=PasReclinerEntrySoftInt.Val
            REC_PasReclinerExitSoftInt_Val: accessed-variable=PasReclinerExitSoftInt.Val
            REC_RtLugSoftInt_Val: accessed-variable=RtLugSoftInt.Val
            REC_RtRcvySoftInt_Val: accessed-variable=RtRcvySoftInt.Val
            REC_RtVipSoftInt_Val: accessed-variable=RtVipSoftInt.Val
            REC_SRSAcsEntry4s2LIntCnt_Val: accessed-variable=SRSAcsEntry4s2LIntCnt.Val
            REC_SRSAcsEntry4s2RIntCnt_Val: accessed-variable=SRSAcsEntry4s2RIntCnt.Val
            REC_SRSAcsEntyIntCnt_Val: accessed-variable=SRSAcsEntyIntCnt.Val
            REC_SRSAcsExit4s2LIntCnt_Val: accessed-variable=SRSAcsExit4s2LIntCnt.Val
            REC_SRSAcsExit4s2RIntCnt_Val: accessed-variable=SRSAcsExit4s2RIntCnt.Val
            REC_SRSAcsExtIntCnt_Val: accessed-variable=SRSAcsExtIntCnt.Val
            REC_SRSAllLugIntCnt_Val: accessed-variable=SRSAllLugIntCnt.Val
            REC_SRSAllVipIntCnt_Val: accessed-variable=SRSAllVipIntCnt.Val
            REC_SRSFamilyLIntCnt_Val: accessed-variable=SRSLtFamilyIntCnt.Val
            REC_SRSFamilyRIntCnt_Val: accessed-variable=SRSRtFamilyIntCnt.Val
            REC_SRSIntimacyIntCnt_Val: accessed-variable=SRSIntimacyLtIntCnt.Val
            REC_SRSIntimacyRtIntCnt_Val: accessed-variable=SRSIntimacyRtIntCnt.Val
            REC_SRSLfLugIntCnt_Val: accessed-variable=SRSLtLugIntCnt.Val
            REC_SRSLfVipIntCnt_Val: accessed-variable=SRSLtVipIntCnt.Val
            REC_SRSLgrstCloseLtIntCnt_Val: accessed-variable=SRSLgrstCloseLtIntCnt.Val
            REC_SRSLgrstCloseRtIntCnt_Val: accessed-variable=SRSLgrstCloseRtIntCnt.Val
            REC_SRSLgrstOpenLtIntCnt_Val: accessed-variable=SRSLgrstOpenLtIntCnt.Val
            REC_SRSLgrstOpenRtIntCnt_Val: accessed-variable=SRSLgrstOpenRtIntCnt.Val
            REC_SRSLyingLIntCnt_Val: accessed-variable=SRSLtLyingIntCnt.Val
            REC_SRSLyingRIntCnt_Val: accessed-variable=SRSRtLyingIntCnt.Val
            REC_SRSRcvyLIntCnt_Val: accessed-variable=SRSLtRcvyIntCnt.Val
            REC_SRSRcvyRIntCnt_Val: accessed-variable=SRSRtRcvyIntCnt.Val
            REC_SRSRtLugIntCnt_Val: accessed-variable=SRSRtLugIntCnt.Val
            REC_SRSRtVipIntCnt_Val: accessed-variable=SRSRtVipIntCnt.Val
            REC_StPassCmprtMdHMIReq_Val: accessed-variable=StPassCmprtMdHMIReq.Val
            REC_SwAcsEntry4s2LIntCnt_Val: accessed-variable=SwAcsEntry4s2LIntCnt.Val
            REC_SwAcsEntry4s2RIntCnt_Val: accessed-variable=SwAcsEntry4s2RIntCnt.Val
            REC_SwAcsEntyBIntCnt_Val: accessed-variable=SwAcsEntyBIntCnt.Val
            REC_SwAcsEntyIntCnt_Val: accessed-variable=SwAcsEntyLIntCnt.Val
            REC_SwAcsEntyRIntCnt_Val: accessed-variable=SwAcsEntyRIntCnt.Val
            REC_SwAcsExit4s2LIntCnt_Val: accessed-variable=SwAcsExit4s2LIntCnt.Val
            REC_SwAcsExit4s2RIntCnt_Val: accessed-variable=SwAcsExit4s2RIntCnt.Val
            REC_SwAcsExtIntCnt_Val: accessed-variable=SwAcsExtLIntCnt.Val
            REC_SwAcsExtRIntCnt_Val: accessed-variable=SwAcsExtRIntCnt.Val
            REC_SwAllLugIntCnt_Val: accessed-variable=SwAllLugIntCnt.Val
            REC_SwLfVipIntCnt_Val: accessed-variable=SwLfVipIntCnt.Val
            REC_SwLtLugIntCnt_Val: accessed-variable=SwLtLugIntCnt.Val
            REC_SwLtRcvyIntCnt_Val: accessed-variable=SwLtRcvyIntCnt.Val
            REC_SwPasReclinerEntryCnt_Val: accessed-variable=SwPasReclinerEntryIntCnt.Val
            REC_SwPasReclinerExitCnt_Val: accessed-variable=SwPasReclinerExitIntCnt.Val
            REC_SwRtLugIntCnt_Val: accessed-variable=SwRtLugIntCnt.Val
            REC_SwRtRcvyIntCnt_Val: accessed-variable=SwRtRcvyIntCnt.Val
            REC_SwRtVipIntCnt_Val: accessed-variable=SwRtVipIntCnt.Val
            REC_SwUnfold3LCnt_Val: accessed-variable=SwUnfold3LIntCnt.Val
            REC_SwUnfold3RCnt_Val: accessed-variable=SwUnfold3RIntCnt.Val
            REC_Unfold3LSoftInt_Val: accessed-variable=Unfold3LSoftInt.Val
            REC_Unfold3RSoftInt_Val: accessed-variable=Unfold3RSoftInt.Val
            REC_VIPAllOutSoftInt_Val: accessed-variable=VIPAllOutSoftInt.Val
            REC_VIPLtOutSoftInt_Val: accessed-variable=VIPLtOutSoftInt.Val
            REC_VIPRtOutSoftInt_Val: accessed-variable=VIPRtOutSoftInt.Val
            REC_WholeVehMem1SoftInt_Val: accessed-variable=WholeVehMem1SoftInt.Val
            REC_WholeVehMem2SoftInt_Val: accessed-variable=WholeVehMem2SoftInt.Val
        data-send-points:
          76 x access:
            SEND_SoftIntAcsEntry4s2L_Val: accessed-variable=SoftIntAcsEntry4s2L.Val
            SEND_SoftIntAcsEntry4s2R_Val: accessed-variable=SoftIntAcsEntry4s2R.Val
            SEND_SoftIntAcsEntryAll4sBwd_Val: accessed-variable=SoftIntAcsEntryAll4sBwd.Val
            SEND_SoftIntAcsEntryAll4sFwd_Val: accessed-variable=SoftIntAcsEntryAll4sFwd.Val
            SEND_SoftIntAcsEnty_Val: accessed-variable=SoftIntAcsEnty.Val
            SEND_SoftIntAcsExit4s2L_Val: accessed-variable=SoftIntAcsExit4s2L.Val
            SEND_SoftIntAcsExit4s2R_Val: accessed-variable=SoftIntAcsExit4s2R.Val
            SEND_SoftIntAcsExt_Val: accessed-variable=SoftIntAcsExt.Val
            SEND_SoftIntAllLug_Val: accessed-variable=SoftIntAllLug.Val
            SEND_SoftIntAllVip_Val: accessed-variable=SoftIntAllVip.Val
            SEND_SoftIntBig4Seat_Val: accessed-variable=SoftIntBig4Seat.Val
            SEND_SoftIntExVIPR_Val: accessed-variable=SoftIntExVIPR.Val
            SEND_SoftIntExVIPROut_Val: accessed-variable=SoftIntExVIPROut.Val
            SEND_SoftIntIntimacy_Val: accessed-variable=SoftIntIntimacyLt.Val
            SEND_SoftIntIntimacyRt_Val: accessed-variable=SoftIntIntimacyRt.Val
            SEND_SoftIntLfLug_Val: accessed-variable=SoftIntLfLug.Val
            SEND_SoftIntLfRcvy_Val: accessed-variable=SoftIntLfRcvy.Val
            SEND_SoftIntLfVip_Val: accessed-variable=SoftIntLfVip.Val
            SEND_SoftIntLgrstCloseLt_Val: accessed-variable=SoftIntLgrstCloseLt.Val
            SEND_SoftIntLgrstCloseRt_Val: accessed-variable=SoftIntLgrstCloseRt.Val
            SEND_SoftIntLgrstOpenLt_Val: accessed-variable=SoftIntLgrstOpenLt.Val
            SEND_SoftIntLgrstOpenRt_Val: accessed-variable=SoftIntLgrstOpenRt.Val
            SEND_SoftIntLtFamily_Val: accessed-variable=SoftIntLtFamily.Val
            SEND_SoftIntLtLying_Val: accessed-variable=SoftIntLtLying.Val
            SEND_SoftIntPasReclinerEntry_Val: accessed-variable=SoftIntPasReclinerEntry.Val
            SEND_SoftIntPasReclinerExit_Val: accessed-variable=SoftIntPasReclinerExit.Val
            SEND_SoftIntRtFamily_Val: accessed-variable=SoftIntRtFamily.Val
            SEND_SoftIntRtLug_Val: accessed-variable=SoftIntRtLug.Val
            SEND_SoftIntRtLying_Val: accessed-variable=SoftIntRtLying.Val
            SEND_SoftIntRtRcvy_Val: accessed-variable=SoftIntRtRcvy.Val
            SEND_SoftIntRtVip_Val: accessed-variable=SoftIntRtVip.Val
            SEND_SoftIntUnfold3L_Val: accessed-variable=SoftIntUnfold3L.Val
            SEND_SoftIntUnfold3R_Val: accessed-variable=SoftIntUnfold3R.Val
            SEND_SoftIntVIPAllOut_Val: accessed-variable=SoftIntVIPAllOut.Val
            SEND_SoftIntVIPLtOut_Val: accessed-variable=SoftIntVIPLtOut.Val
            SEND_SoftIntVIPRtOut_Val: accessed-variable=SoftIntVIPRtOut.Val
            SEND_SoftIntWholeVehMem1_Val: accessed-variable=SoftIntWholeVehMem1.Val
            SEND_SoftIntWholeVehMem2_Val: accessed-variable=SoftIntWholeVehMem2.Val
            SEND_SwIntAcsEntry4s2L_Val: accessed-variable=SwIntAcsEntry4s2L.Val
            SEND_SwIntAcsEntry4s2R_Val: accessed-variable=SwIntAcsEntry4s2R.Val
            SEND_SwIntAcsEntryAll4sBwd_Val: accessed-variable=SwIntAcsEntryAll4sBwd.Val
            SEND_SwIntAcsEntryAll4sFwd_Val: accessed-variable=SwIntAcsEntryAll4sFwd.Val
            SEND_SwIntAcsEnty_Val: accessed-variable=SwIntAcsEnty.Val
            SEND_SwIntAcsExit4s2L_Val: accessed-variable=SwIntAcsExit4s2L.Val
            SEND_SwIntAcsExit4s2R_Val: accessed-variable=SwIntAcsExit4s2R.Val
            SEND_SwIntAcsExt_Val: accessed-variable=SwIntAcsExt.Val
            SEND_SwIntAllLug_Val: accessed-variable=SwIntAllLug.Val
            SEND_SwIntAllVip_Val: accessed-variable=SwIntAllVip.Val
            SEND_SwIntAllVipOut_Val: accessed-variable=SwIntAllVipOut.Val
            SEND_SwIntBig4Seat_Val: accessed-variable=SwIntBig4Seat.Val
            SEND_SwIntExVIPR_Val: accessed-variable=SwIntExVIPR.Val
            SEND_SwIntExVIPROut_Val: accessed-variable=SwIntExVIPROut.Val
            SEND_SwIntIntimacy_Val: accessed-variable=SwIntIntimacyLt.Val
            SEND_SwIntIntimacyRt_Val: accessed-variable=SwIntIntimacyRt.Val
            SEND_SwIntLfLug_Val: accessed-variable=SwIntLfLug.Val
            SEND_SwIntLfRcvy_Val: accessed-variable=SwIntLfRcvy.Val
            SEND_SwIntLfVip_Val: accessed-variable=SwIntLfVip.Val
            SEND_SwIntLfVipOut_Val: accessed-variable=SwIntLfVipOut.Val
            SEND_SwIntLgrstCloseLt_Val: accessed-variable=SwIntLgrstCloseLt.Val
            SEND_SwIntLgrstCloseRt_Val: accessed-variable=SwIntLgrstCloseRt.Val
            SEND_SwIntLgrstOpenLt_Val: accessed-variable=SwIntLgrstOpenLt.Val
            SEND_SwIntLgrstOpenRt_Val: accessed-variable=SwIntLgrstOpenRt.Val
            SEND_SwIntLtFamily_Val: accessed-variable=SwIntLtFamily.Val
            SEND_SwIntLtLying_Val: accessed-variable=SwIntLtLying.Val
            SEND_SwIntPasReclinerEntry_Val: accessed-variable=SwIntPasReclinerEntry.Val
            SEND_SwIntPasReclinerExit_Val: accessed-variable=SwIntPasReclinerExit.Val
            SEND_SwIntRtFamily_Val: accessed-variable=SwIntRtFamily.Val
            SEND_SwIntRtLug_Val: accessed-variable=SwIntRtLug.Val
            SEND_SwIntRtLying_Val: accessed-variable=SwIntRtLying.Val
            SEND_SwIntRtRcvy_Val: accessed-variable=SwIntRtRcvy.Val
            SEND_SwIntRtVip_Val: accessed-variable=SwIntRtVip.Val
            SEND_SwIntRtVipOut_Val: accessed-variable=SwIntRtVipOut.Val
            SEND_SwIntUnfold3L_Val: accessed-variable=SwIntUnfold3L.Val
            SEND_SwIntUnfold3R_Val: accessed-variable=SwIntUnfold3R.Val
            SEND_SwIntWholeVehMem1_Val: accessed-variable=SwIntWholeVehMem1.Val
            SEND_SwIntWholeVehMem2_Val: accessed-variable=SwIntWholeVehMem2.Val
  swc implementation ModeInt_Implementation: behavior=ModeInt_InternalBehavior
    code-descriptors:
      code Default: artifact-descriptors=autosar-engineering-object={short-label=Default, category=SWSRC}
package /PATAC/MSM/ModeAdjust/DataType
  impl type CmprtMdHMIReqTp1: category=VALUE, base-type=UInt8, sw-calibration-access=READ-ONLY, compu {0=CmprtMdHMIReqTp_NoAction, 1..14=CmprtMdHMIReqTp_Mode1..CmprtMdHMIReqTp_Mode14, 15=CmprtMdHMIReqTp_Stop}, type-emitter=RTE
  impl type MdReqTp1: category=VALUE, base-type=UInt8, sw-calibration-access=READ-ONLY, compu {0=MdReqTp_NoAction, 1=MdReqTp_Start, 2=MdReqTp_Stop, 3=MdReqTp_Cancel}, type-emitter=RTE
package /PATAC/MSM/ModeAdjust/PortInterface
  5 x sender receiver interface:
    HMIRclReq: invalidation-policy{data-element=HMIRclReq/Val, handle-invalid=DONT-INVALIDATE}
      data Val: type=MdReqTp1
    IfVeSMSeStNumConfig: invalidation-policy{data-element=IfVeSMSeStNumConfig/Val, handle-invalid=DONT-INVALIDATE}
      data Val: type=IfVeSMSeStNumConfig
    IntEnable: invalidation-policy{data-element=IntEnable/Val, handle-invalid=DONT-INVALIDATE}
      data Val: type=IntEnable
    StPassCmprtMdHMIReq: invalidation-policy{data-element=StPassCmprtMdHMIReq/Val, handle-invalid=DONT-INVALIDATE}
      data Val: type=CmprtMdHMIReqTp1
    SwModeIntCnt: invalidation-policy{data-element=SwModeIntCnt/Val, handle-invalid=DONT-INVALIDATE}
      data Val: type=IntCnt
package /PortInterfaces
  sender receiver interface SeatSwActive: invalidation-policy{data-element=SeatSwActive/Val, handle-invalid=DONT-INVALIDATE}
    data Val: type=Boolean
